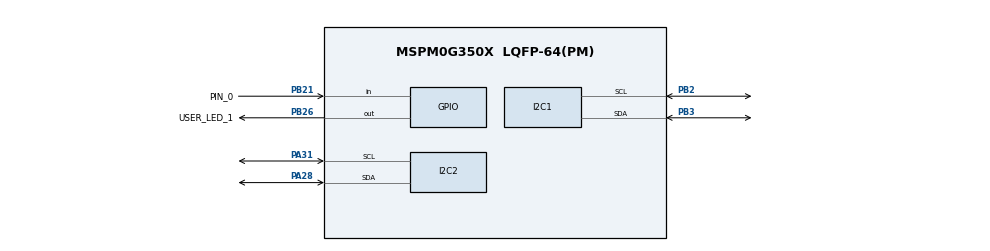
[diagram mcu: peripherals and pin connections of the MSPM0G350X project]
/**
 * @cliArgs --device "MSPM0G350X" --part "Default" --package "LQFP-64(PM)" --product "mspm0_sdk@2.05.01.01"
 * @versions {"tool":"1.24.0+4110"}
 */

/**
 * Import the modules used in this configuration.
 */
const Board         = scripting.addModule("/ti/driverlib/Board");
const GPIO          = scripting.addModule("/ti/driverlib/GPIO", {}, false);
const GPIO1         = GPIO.addInstance();
const GPIO2         = GPIO.addInstance();
const I2C           = scripting.addModule("/ti/driverlib/I2C", {}, false);
const I2C1          = I2C.addInstance();
const I2C2          = I2C.addInstance();
const SYSCTL        = scripting.addModule("/ti/driverlib/SYSCTL");
const ProjectConfig = scripting.addModule("/ti/project_config/ProjectConfig");

/**
 * Write custom configuration values to the imported modules.
 */

GPIO1.$name                         = "GPIO_LEDS";
GPIO1.port                          = "PORTB";
GPIO1.associatedPins[0].$name       = "USER_LED_1";
GPIO1.associatedPins[0].pin.$assign = "PB26";

GPIO2.$name                              = "GPIO_GRP_0";
GPIO2.port                               = "PORTB";
GPIO2.associatedPins[0].$name            = "PIN_0";
GPIO2.associatedPins[0].direction        = "INPUT";
GPIO2.associatedPins[0].interruptEn      = true;
GPIO2.associatedPins[0].polarity         = "FALL";
GPIO2.associatedPins[0].internalResistor = "PULL_UP";
GPIO2.associatedPins[0].assignedPin      = "21";
GPIO2.associatedPins[0].pin.$assign      = "PB21";

I2C1.$name                     = "I2C_0";
I2C1.basicEnableController     = true;
I2C1.advAnalogGlitchFilter     = "DISABLED";
I2C1.advControllerTXFIFOTRIG   = "BYTES_1";
I2C1.peripheral.sdaPin.$assign = "PB3";
I2C1.peripheral.sclPin.$assign = "PB2";
I2C1.sdaPinConfig.$name        = "ti_driverlib_gpio_GPIOPinGeneric0";
I2C1.sdaPinConfig.enableConfig = true;
I2C1.sclPinConfig.$name        = "ti_driverlib_gpio_GPIOPinGeneric1";

I2C2.$name                     = "I2C_1";
I2C2.basicEnableTarget         = true;
I2C2.basicTargetAddress        = 0x48;
I2C2.advAnalogGlitchFilter     = "DISABLED";
I2C2.advTargetTXFIFOTRIG       = "BYTES_1";
I2C2.advTargetTXEmptyEn        = true;
I2C2.intTarget                 = ["RXFIFO_TRIGGER","START","STOP"];
I2C2.peripheral.$assign        = "I2C0";
I2C2.peripheral.sdaPin.$assign = "PA28";
I2C2.peripheral.sclPin.$assign = "PA31";
I2C2.sdaPinConfig.$name        = "ti_driverlib_gpio_GPIOPinGeneric2";
I2C2.sclPinConfig.$name        = "ti_driverlib_gpio_GPIOPinGeneric3";

SYSCTL.clockTreeEn           = true;
SYSCTL.forceDefaultClkConfig = true;

/**
 * Pinmux solution for unlocked pins/peripherals. This ensures that minor changes to the automatic solver in a future
 * version of the tool will not impact the pinmux you originally saw.  These lines can be completely deleted in order to
 * re-solve from scratch.
 */
Board.peripheral.$suggestSolution          = "DEBUGSS";
Board.peripheral.swclkPin.$suggestSolution = "PA20";
Board.peripheral.swdioPin.$suggestSolution = "PA19";
I2C1.peripheral.$suggestSolution           = "I2C1";
